# TM4C123BH6PGE register map
Vendor: Texas Instruments; File version: 11073
CPU: CM4 r1p2, little endian, no MPU, no FPU, 0x3 interrupt priority bits, 0x0 interrupts
Registers are 32-bit, read-write, no defined reset value unless marked. A register's access mark holds for its fields unless they carry their own. Offsets are from the block's base; [hi:lo] are bit positions; {n}, {i} and the like mark numbered series.

## COMP — Register map for COMP peripheral
Base 0x4003C000; register names take the prefix COMP
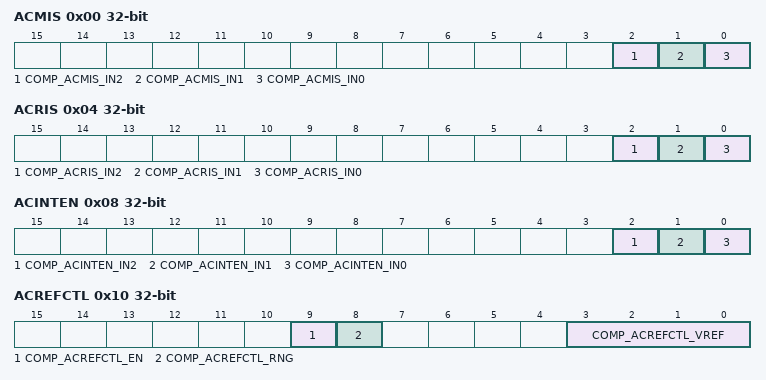
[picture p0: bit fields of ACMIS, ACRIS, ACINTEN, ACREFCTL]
0x00 ACMIS — Analog Comparator Masked Interrupt Status
  [2] COMP_ACMIS_IN2 — Comparator 2 Masked Interrupt Status
  [1] COMP_ACMIS_IN1 — Comparator 1 Masked Interrupt Status
  [0] COMP_ACMIS_IN0 — Comparator 0 Masked Interrupt Status
0x04 ACRIS — Analog Comparator Raw Interrupt Status
  [2] COMP_ACRIS_IN2 — Comparator 2 Interrupt Status
  [1] COMP_ACRIS_IN1 — Comparator 1 Interrupt Status
  [0] COMP_ACRIS_IN0 — Comparator 0 Interrupt Status
0x08 ACINTEN — Analog Comparator Interrupt Enable
  [2] COMP_ACINTEN_IN2 — Comparator 2 Interrupt Enable
  [1] COMP_ACINTEN_IN1 — Comparator 1 Interrupt Enable
  [0] COMP_ACINTEN_IN0 — Comparator 0 Interrupt Enable
0x10 ACREFCTL — Analog Comparator Reference Voltage Control
  [9] COMP_ACREFCTL_EN — Resistor Ladder Enable
  [8] COMP_ACREFCTL_RNG — Resistor Ladder Range
  [3:0] COMP_ACREFCTL_VREF — Resistor Ladder Voltage Ref
{0x20+0x20*i} ACSTAT{i} (i=0..2) — Analog Comparator Status {i}
  [1] COMP_ACSTAT{i}_OVAL — Comparator Output Value
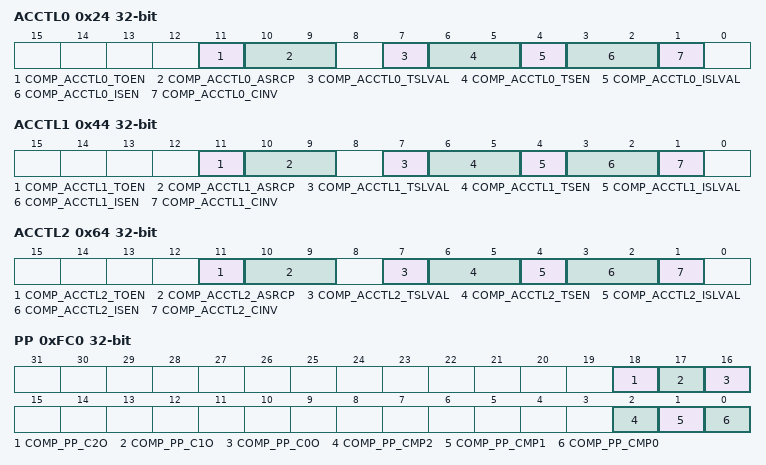
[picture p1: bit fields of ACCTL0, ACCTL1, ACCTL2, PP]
0x24 ACCTL0 — Analog Comparator Control 0
  [11] COMP_ACCTL0_TOEN — Trigger Output Enable
  [10:9] COMP_ACCTL0_ASRCP — Analog Source Positive
    0=COMP_ACCTL0_ASRCP_PIN (Pin value of Cn+); 1=COMP_ACCTL0_ASRCP_PIN0 (Pin value of C0+); 2=COMP_ACCTL0_ASRCP_REF (Internal voltage reference)
  [7] COMP_ACCTL0_TSLVAL — Trigger Sense Level Value
  [6:5] COMP_ACCTL0_TSEN — Trigger Sense
    0=COMP_ACCTL0_TSEN_LEVEL (Level sense, see TSLVAL); 1=COMP_ACCTL0_TSEN_FALL (Falling edge); 2=COMP_ACCTL0_TSEN_RISE (Rising edge); 3=COMP_ACCTL0_TSEN_BOTH (Either edge)
  [4] COMP_ACCTL0_ISLVAL — Interrupt Sense Level Value
  [3:2] COMP_ACCTL0_ISEN — Interrupt Sense
    0=COMP_ACCTL0_ISEN_LEVEL (Level sense, see ISLVAL); 1=COMP_ACCTL0_ISEN_FALL (Falling edge); 2=COMP_ACCTL0_ISEN_RISE (Rising edge); 3=COMP_ACCTL0_ISEN_BOTH (Either edge)
  [1] COMP_ACCTL0_CINV — Comparator Output Invert
0x44 ACCTL1 — Analog Comparator Control 1
  [11] COMP_ACCTL1_TOEN — Trigger Output Enable
  [10:9] COMP_ACCTL1_ASRCP — Analog Source Positive
    0=COMP_ACCTL1_ASRCP_PIN (Pin value of Cn+); 1=COMP_ACCTL1_ASRCP_PIN0 (Pin value of C0+); 2=COMP_ACCTL1_ASRCP_REF (Internal voltage reference (VIREF))
  [7] COMP_ACCTL1_TSLVAL — Trigger Sense Level Value
  [6:5] COMP_ACCTL1_TSEN — Trigger Sense
    0=COMP_ACCTL1_TSEN_LEVEL (Level sense, see TSLVAL); 1=COMP_ACCTL1_TSEN_FALL (Falling edge); 2=COMP_ACCTL1_TSEN_RISE (Rising edge); 3=COMP_ACCTL1_TSEN_BOTH (Either edge)
  [4] COMP_ACCTL1_ISLVAL — Interrupt Sense Level Value
  [3:2] COMP_ACCTL1_ISEN — Interrupt Sense
    0=COMP_ACCTL1_ISEN_LEVEL (Level sense, see ISLVAL); 1=COMP_ACCTL1_ISEN_FALL (Falling edge); 2=COMP_ACCTL1_ISEN_RISE (Rising edge); 3=COMP_ACCTL1_ISEN_BOTH (Either edge)
  [1] COMP_ACCTL1_CINV — Comparator Output Invert
0x64 ACCTL2 — Analog Comparator Control 2
  [11] COMP_ACCTL2_TOEN — Trigger Output Enable
  [10:9] COMP_ACCTL2_ASRCP — Analog Source Positive
    0=COMP_ACCTL2_ASRCP_PIN (Pin value of Cn+); 1=COMP_ACCTL2_ASRCP_PIN0 (Pin value of C0+); 2=COMP_ACCTL2_ASRCP_REF (Internal voltage reference (VIREF))
  [7] COMP_ACCTL2_TSLVAL — Trigger Sense Level Value
  [6:5] COMP_ACCTL2_TSEN — Trigger Sense
    0=COMP_ACCTL2_TSEN_LEVEL (Level sense, see TSLVAL); 1=COMP_ACCTL2_TSEN_FALL (Falling edge); 2=COMP_ACCTL2_TSEN_RISE (Rising edge); 3=COMP_ACCTL2_TSEN_BOTH (Either edge)
  [4] COMP_ACCTL2_ISLVAL — Interrupt Sense Level Value
  [3:2] COMP_ACCTL2_ISEN — Interrupt Sense
    0=COMP_ACCTL2_ISEN_LEVEL (Level sense, see ISLVAL); 1=COMP_ACCTL2_ISEN_FALL (Falling edge); 2=COMP_ACCTL2_ISEN_RISE (Rising edge); 3=COMP_ACCTL2_ISEN_BOTH (Either edge)
  [1] COMP_ACCTL2_CINV — Comparator Output Invert
0xFC0 PP — Analog Comparator Peripheral Properties
  [18] COMP_PP_C2O — Comparator Output 2 Present
  [17] COMP_PP_C1O — Comparator Output 1 Present
  [16] COMP_PP_C0O — Comparator Output 0 Present
  [2] COMP_PP_CMP2 — Comparator 2 Present
  [1] COMP_PP_CMP1 — Comparator 1 Present
  [0] COMP_PP_CMP0 — Comparator 0 Present
